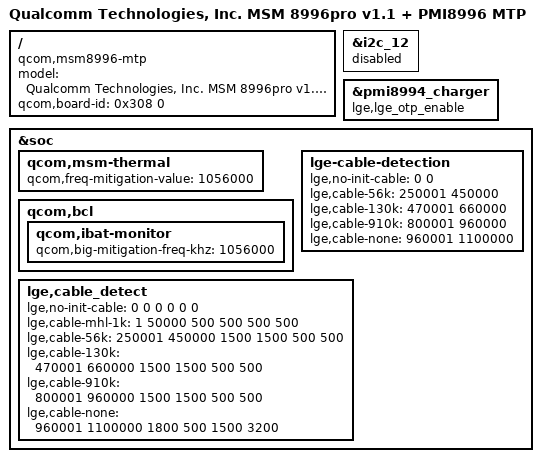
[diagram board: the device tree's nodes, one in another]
/* Copyright (c) 2015, The Linux Foundation. All rights reserved.
 *
 * This program is free software; you can redistribute it and/or modify
 * it under the terms of the GNU General Public License version 2 and
 * only version 2 as published by the Free Software Foundation.
 *
 * This program is distributed in the hope that it will be useful,
 * but WITHOUT ANY WARRANTY; without even the implied warranty of
 * MERCHANTABILITY or FITNESS FOR A PARTICULAR PURPOSE.  See the
 * GNU General Public License for more details.
 */


/dts-v1/;

#include "../../qcom/msm8996pro-v1.1.dtsi"
#include "../../qcom/msm-pmi8996.dtsi"
#include "msm8996-falcon_kr.dtsi"
#include "msm8996-falcon_kr-touch.dtsi"
#include "../msm8996-camera/msm8996-falcon-camera_rev-0.0.dtsi"
#include "../msm8996-falcon_storage_type/current_storage_type.dtsi"
#include "../msm8996-sound/msm8996-falcon-sound_rev-a.dtsi"
#include "../msm8996pro-tdmb/msm8996pro-falcon_kr-tdmb.dtsi"
#include "msm8996-falcon_kr-sound.dtsi"
#include "../msm8996-falcon-common/msm8996-falcon-common-usb-rev-1.0.dtsi"


/ {
	model = "Qualcomm Technologies, Inc. MSM 8996pro v1.1 + PMI8996 MTP";
	compatible = "qcom,msm8996-mtp", "qcom,msm8996", "qcom,mtp";
	qcom,board-id = <0x308 0>;
};

&i2c_12 {
	status = "disabled";
};


&pmi8994_charger {
    lge,lge_otp_enable;
};

&soc {
	qcom,msm-thermal {
		qcom,freq-mitigation-value = <1056000>;
	};
	qcom,bcl {
		qcom,ibat-monitor {
			qcom,big-mitigation-freq-khz = <1056000>;
		};
	};

    lge-cable-detection {
		// < down_threshold, up_threshold >
		lge,no-init-cable 	= <      0       0>;
		lge,cable-56k 		= < 250001  450000>;
		lge,cable-130k 		= < 470001  660000>;
		lge,cable-910k 		= < 800001  960000>;
		lge,cable-none 		= < 960001 1100000>;
	};
    lge,cable_detect {
		lge,no-init-cable       = <     0       0    0   0    0     0>;
		lge,cable-mhl-1k        = <     1   50000  500  500  500  500>;
		lge,cable-56k           = <250001  450000 1500 1500  500  500>;
		lge,cable-130k          = <470001  660000 1500 1500  500  500>;
		lge,cable-910k          = <800001  960000 1500 1500  500  500>;
		lge,cable-none          = <960001 1100000 1800  500 1500 3200>;
	};
};
